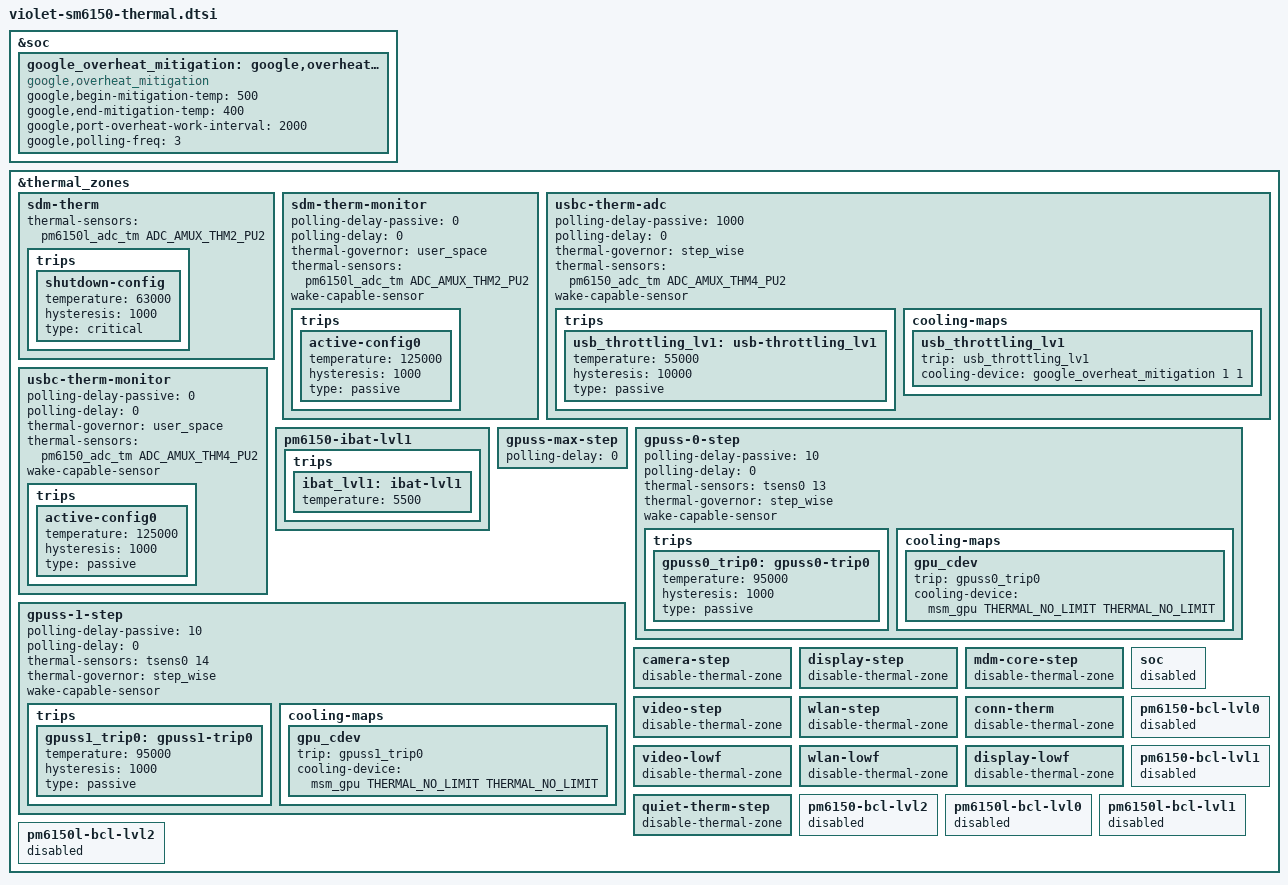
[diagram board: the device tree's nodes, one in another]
/* Copyright (c) 2020, The Linux Foundation. All rights reserved.
 *
 * This program is free software; you can redistribute it and/or modify
 * it under the terms of the GNU General Public License version 2 and
 * only version 2 as published by the Free Software Foundation.
 *
 * This program is distributed in the hope that it will be useful,
 * but WITHOUT ANY WARRANTY; without even the implied warranty of
 * MERCHANTABILITY or FITNESS FOR A PARTICULAR PURPOSE.  See the
 * GNU General Public License for more details.
 */

&soc {
	google_overheat_mitigation: google,overheat_mitigation {
		compatible = "google,overheat_mitigation";
		#cooling-cells = <2>;
		google,begin-mitigation-temp = <500>;
		google,end-mitigation-temp = <400>;
		google,port-overheat-work-interval = <2000>;
		/* Must maintain < 1/15 duty cycle */
		google,polling-freq = <3>;
	};
};

 &thermal_zones {
	sdm-therm {
		thermal-sensors = <&pm6150l_adc_tm ADC_AMUX_THM2_PU2>;
		trips {
			shutdown-config {
				temperature = <63000>;
				hysteresis = <1000>;
				type = "critical";
			};
		};
	};

	sdm-therm-monitor {
		polling-delay-passive = <0>;
		polling-delay = <0>;
		thermal-governor = "user_space";
		thermal-sensors = <&pm6150l_adc_tm ADC_AMUX_THM2_PU2>;
		wake-capable-sensor;
		trips {
			active-config0 {
				temperature = <125000>;
				hysteresis = <1000>;
				type = "passive";
			};
		};
	};

	usbc-therm-adc {
		polling-delay-passive = <1000>;
		polling-delay = <0>;
		thermal-governor = "step_wise";
		thermal-sensors = <&pm6150_adc_tm ADC_AMUX_THM4_PU2>;
		wake-capable-sensor;
		trips {
			usb_throttling_lv1: usb-throttling_lv1 {
				temperature = <55000>;
				hysteresis = <10000>;
				type = "passive";
			};
		};
		cooling-maps {
			usb_throttling_lv1 {
				trip = <&usb_throttling_lv1>;
				cooling-device =
					<&google_overheat_mitigation 1 1>;
			};
		};
	};

	usbc-therm-monitor {
		polling-delay-passive = <0>;
		polling-delay = <0>;
		thermal-governor = "user_space";
		thermal-sensors = <&pm6150_adc_tm ADC_AMUX_THM4_PU2>;
		wake-capable-sensor;
		trips {
			active-config0 {
				temperature = <125000>;
				hysteresis = <1000>;
				type = "passive";
			};
		};
	};

	pm6150-ibat-lvl1 {
		trips {
			ibat_lvl1:ibat-lvl1 {
				temperature = <5500>;
			};
		};
	};

	gpuss-max-step {
		polling-delay = <0>;
	};

	gpuss-0-step {
		polling-delay-passive = <10>;
		polling-delay = <0>;
		thermal-sensors = <&tsens0 13>;
		thermal-governor = "step_wise";
		wake-capable-sensor;
		trips {
			gpuss0_trip0: gpuss0-trip0 {
				temperature = <95000>;
				hysteresis = <1000>;
				type = "passive";
			};
		};

		cooling-maps {
			gpu_cdev {
				trip = <&gpuss0_trip0>;
				cooling-device = <&msm_gpu THERMAL_NO_LIMIT
							THERMAL_NO_LIMIT>;
			};
		};
	};

	gpuss-1-step {
		polling-delay-passive = <10>;
		polling-delay = <0>;
		thermal-sensors = <&tsens0 14>;
		thermal-governor = "step_wise";
		wake-capable-sensor;
		trips {
			gpuss1_trip0: gpuss1-trip0 {
				temperature = <95000>;
				hysteresis = <1000>;
				type = "passive";
			};
		};

		cooling-maps {
			gpu_cdev {
				trip = <&gpuss1_trip0>;
				cooling-device = <&msm_gpu THERMAL_NO_LIMIT
							THERMAL_NO_LIMIT>;
			};
		};
	};

	/* Remove redundant QCT thermal zones */
	camera-step {
		disable-thermal-zone;
	};

	display-step {
		disable-thermal-zone;
	};

	mdm-core-step {
		disable-thermal-zone;
	};

	video-step {
		disable-thermal-zone;
	};

	wlan-step {
		disable-thermal-zone;
	};

	conn-therm {
		disable-thermal-zone;
	};

	video-lowf {
		disable-thermal-zone;
	};

	wlan-lowf {
		disable-thermal-zone;
	};

	display-lowf {
		disable-thermal-zone;
	};

	quiet-therm-step {
		disable-thermal-zone;
	};

	/* Disable QCT default BCL throttling */
	soc {
		status = "disabled";
	};

	pm6150-bcl-lvl0 {
		status = "disabled";
	};

	pm6150-bcl-lvl1	{
		status = "disabled";
	};

	pm6150-bcl-lvl2	{
		status = "disabled";
	};

	pm6150l-bcl-lvl0 {
		status = "disabled";
	};

	pm6150l-bcl-lvl1 {
		status = "disabled";
	};

	pm6150l-bcl-lvl2 {
		status = "disabled";
	};
};
